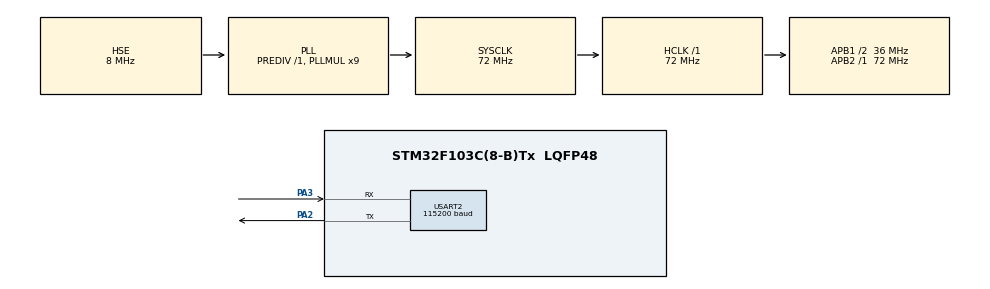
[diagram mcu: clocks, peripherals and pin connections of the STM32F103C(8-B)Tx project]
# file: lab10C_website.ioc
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Mcu.Family=STM32F1
Mcu.Name=STM32F103C(8-B)Tx
Mcu.Package=LQFP48
NVIC.PriorityGroup=NVIC_PRIORITYGROUP_4
PA3.Mode=Asynchronous
PA3.Signal=USART2_RX
PA13.Mode=Serial_Wire
PA13.Signal=SYS_JTMS-SWDIO
PA14.Mode=Serial_Wire
PA14.Signal=SYS_JTCK-SWCLK
PA2.Mode=Asynchronous
PA2.Signal=USART2_TX
PD0-OSC_IN.Mode=HSE-External-Oscillator
PD0-OSC_IN.Signal=RCC_OSC_IN
PD1-OSC_OUT.Mode=HSE-External-Oscillator
PD1-OSC_OUT.Signal=RCC_OSC_OUT
ProjectManager.HeapSize=0x200
ProjectManager.StackSize=0x400
ProjectManager.TargetToolchain=MDK-ARM V5.32
RCC.AHBFreq_Value=72000000
RCC.APB1CLKDivider=RCC_HCLK_DIV2
RCC.APB1Freq_Value=36000000
RCC.APB1TimFreq_Value=72000000
RCC.APB2Freq_Value=72000000
RCC.APB2TimFreq_Value=72000000
RCC.HCLKFreq_Value=72000000
RCC.PLLMUL=RCC_PLL_MUL9
RCC.PLLSourceVirtual=RCC_PLLSOURCE_HSE
RCC.SYSCLKFreq_VALUE=72000000
RCC.SYSCLKSource=RCC_SYSCLKSOURCE_PLLCLK
RCC.USBFreq_Value=72000000
USART2.BaudRate=115200
USART2.VirtualMode=VM_ASYNC
board=custom

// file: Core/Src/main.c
/* USER CODE BEGIN Header */
/**
  ******************************************************************************
  * @file           : main.c
  * @brief          : Main program body
  ******************************************************************************
  * @attention
  *
  * Copyright (c) 2026 STMicroelectronics.
  * All rights reserved.
  *
  * This software is licensed under terms that can be found in the LICENSE file
  * in the root directory of this software component.
  * If no LICENSE file comes with this software, it is provided AS-IS.
  *
  ******************************************************************************
  */
/* USER CODE END Header */
#include "main.h"

/* USER CODE BEGIN Includes */
#include <string.h>
#include <stdio.h>
/* USER CODE END Includes */

UART_HandleTypeDef huart2;

void SystemClock_Config(void);
static void MX_GPIO_Init(void);
static void MX_USART2_UART_Init(void);

/* USER CODE BEGIN 0 */
	uint8_t rx_data[800];
	uint8_t rx_char;
	uint16_t array_index;
	uint8_t cmd1[] = "AT\r\n";
	uint8_t cmd2[] = "AT+CWMODE=1\r\n";
	uint8_t cmd3[] = "AT+CWJAP=\"YOUR_WIFI_SSID\",\"YOUR_WIFI_PASSWORD\"\r\n";
	uint8_t cmd4[] = "AT+CIFSR\r\n";
	uint8_t cmd5[] = "AT+CIPMUX=1\r\n";
	uint8_t cmd6[] = "AT+CIPSERVER=1,80\r\n";
	char response[300];
	char cmd[50];
	uint32_t counter = 0;
	char body[150];

	void clear_buffer(void)
	{
		memset(rx_data, 0, sizeof(rx_data));
		array_index = 0;
		}
		void receive_response(void)
		{
			while (1)
			{
			if (HAL_UART_Receive(&huart2, &rx_char, 1, 20000) == HAL_OK)
			{
				if (array_index < 799)
				{
				rx_data[array_index] = rx_char;
				array_index++;
				rx_data[array_index] = '\0';
				}

				if (strstr((char *)rx_data, "OK") != NULL)
				{
				break;
				}
				if (strstr((char *)rx_data, "ERROR") != NULL ||
				strstr((char *)rx_data, "FAIL") != NULL)
				{
				break;
				}
				if (strstr((char *)rx_data, "<") != NULL)
				{
				break;
				}
				}
			else
				{
				break;
				}
	}
	}

void send_http_response(int conn_id)
{
    counter++;

    sprintf(body,
            "<html><body>"
						"<h1>New num %lu</h1>"
            "</body></html>",
            (unsigned long)counter);

    sprintf(response,
            "HTTP/1.1 200 OK\r\n"
            "Content-Type: text/html\r\n"
            "Content-Length: %d\r\n"
            "Connection: close\r\n"
            "\r\n"
            "%s",
            (int)strlen(body), body);

    sprintf(cmd, "AT+CIPSEND=%d,%d\r\n", conn_id, (int)strlen(response));

    HAL_UART_Transmit(&huart2, (uint8_t *)cmd, strlen(cmd), 1000);

    while (HAL_UART_Receive(&huart2, &rx_char, 1, 5000) == HAL_OK)
    {
        if (rx_char == '>')
            break;
    }

    HAL_UART_Transmit(&huart2, (uint8_t *)response, strlen(response), 5000);

    receive_response();

    sprintf(cmd, "AT+CIPCLOSE=%d\r\n", conn_id);
    HAL_UART_Transmit(&huart2, (uint8_t *)cmd, strlen(cmd), 1000);
    receive_response();
}

/* USER CODE END 0 */

int main(void)
{

  /* MCU Configuration--------------------------------------------------------*/

  /* Reset of all peripherals, Initializes the Flash interface and the Systick. */
  HAL_Init();

  /* Configure the system clock */
  SystemClock_Config();

  /* Initialize all configured peripherals */
  MX_GPIO_Init();
  MX_USART2_UART_Init();
  /* USER CODE BEGIN 2 */
	HAL_Delay(2000);
	clear_buffer();
	HAL_UART_Transmit(&huart2, cmd1, strlen((char *)cmd1), HAL_MAX_DELAY);
	receive_response();
	clear_buffer();
	HAL_UART_Transmit(&huart2, cmd2, strlen((char *)cmd2), HAL_MAX_DELAY);
	receive_response();
	clear_buffer();
	HAL_UART_Transmit(&huart2, cmd3, strlen((char *)cmd3), HAL_MAX_DELAY);
	receive_response();
	clear_buffer();
	HAL_UART_Transmit(&huart2, cmd4, strlen((char *)cmd4), HAL_MAX_DELAY);
	receive_response();
	clear_buffer();
	HAL_UART_Transmit(&huart2, cmd5, strlen((char *)cmd5), HAL_MAX_DELAY);
	receive_response();
	clear_buffer();
	HAL_UART_Transmit(&huart2, cmd6, strlen((char *)cmd6), HAL_MAX_DELAY);
	receive_response();

  /* USER CODE END 2 */

/* Infinite loop */
while (1)
{

    /* USER CODE BEGIN 3 */

    if (HAL_UART_Receive(&huart2, &rx_char, 1, 100) == HAL_OK)
    {
        if (array_index < sizeof(rx_data) - 1)
        {
            rx_data[array_index++] = rx_char;
            rx_data[array_index] = '\0';
        }
        else
        {
            /* Buffer full - reset to avoid overflow */
            clear_buffer();
        }

        /* Detect incoming +IPD client connection with HTTP GET request */
        if (strstr((char *)rx_data, "+IPD,") != NULL &&
            strstr((char *)rx_data, "GET /") != NULL)
        {
            /* Extract connection ID from +IPD,<id>,<len>: format */
            char *ipd_ptr = strstr((char *)rx_data, "+IPD,");
            if (ipd_ptr != NULL)
            {
                int conn_id = ipd_ptr[5] - '0'; /* Single digit connection ID */

                /* Build and send HTTP response */
                send_http_response(conn_id);
            }

            clear_buffer();
        }
    }
}
/* USER CODE END 3 */
}

void SystemClock_Config(void)
{
  RCC_OscInitTypeDef RCC_OscInitStruct = {0};
  RCC_ClkInitTypeDef RCC_ClkInitStruct = {0};

  /** Initializes the RCC Oscillators according to the specified parameters
  * in the RCC_OscInitTypeDef structure.
  */
  RCC_OscInitStruct.OscillatorType = RCC_OSCILLATORTYPE_HSE;
  RCC_OscInitStruct.HSEState = RCC_HSE_ON;
  RCC_OscInitStruct.HSEPredivValue = RCC_HSE_PREDIV_DIV1;
  RCC_OscInitStruct.HSIState = RCC_HSI_ON;
  RCC_OscInitStruct.PLL.PLLState = RCC_PLL_ON;
  RCC_OscInitStruct.PLL.PLLSource = RCC_PLLSOURCE_HSE;
  RCC_OscInitStruct.PLL.PLLMUL = RCC_PLL_MUL9;
  if (HAL_RCC_OscConfig(&RCC_OscInitStruct) != HAL_OK)
  {
    Error_Handler();
  }

  /** Initializes the CPU, AHB and APB buses clocks
  */
  RCC_ClkInitStruct.ClockType = RCC_CLOCKTYPE_HCLK|RCC_CLOCKTYPE_SYSCLK
                              |RCC_CLOCKTYPE_PCLK1|RCC_CLOCKTYPE_PCLK2;
  RCC_ClkInitStruct.SYSCLKSource = RCC_SYSCLKSOURCE_PLLCLK;
  RCC_ClkInitStruct.AHBCLKDivider = RCC_SYSCLK_DIV1;
  RCC_ClkInitStruct.APB1CLKDivider = RCC_HCLK_DIV2;
  RCC_ClkInitStruct.APB2CLKDivider = RCC_HCLK_DIV1;

  if (HAL_RCC_ClockConfig(&RCC_ClkInitStruct, FLASH_LATENCY_2) != HAL_OK)
  {
    Error_Handler();
  }
}

static void MX_USART2_UART_Init(void)
{

  huart2.Instance = USART2;
  huart2.Init.BaudRate = 115200;
  huart2.Init.WordLength = UART_WORDLENGTH_8B;
  huart2.Init.StopBits = UART_STOPBITS_1;
  huart2.Init.Parity = UART_PARITY_NONE;
  huart2.Init.Mode = UART_MODE_TX_RX;
  huart2.Init.HwFlowCtl = UART_HWCONTROL_NONE;
  huart2.Init.OverSampling = UART_OVERSAMPLING_16;
  if (HAL_UART_Init(&huart2) != HAL_OK)
  {
    Error_Handler();
  }

}

static void MX_GPIO_Init(void)
{

  /* GPIO Ports Clock Enable */
  __HAL_RCC_GPIOD_CLK_ENABLE();
  __HAL_RCC_GPIOA_CLK_ENABLE();

}

void Error_Handler(void)
{
  __disable_irq();
  while (1)
  {
  }
}
